# STM32F407 register map
File version: 1.4
CPU: CM4 r0p1, little endian, MPU, FPU, 4 interrupt priority bits
Registers are 32-bit, read-write, reset 0x0 unless marked. A register's access mark holds for its fields unless they carry their own. Offsets are from the block's base; [hi:lo] are bit positions; {n}, {i} and the like mark numbered series; 'fields as' and 'values as' point back to an identical list.

## OTG_FS_PWRCLK — USB on the go full speed
Base 0x50000E00
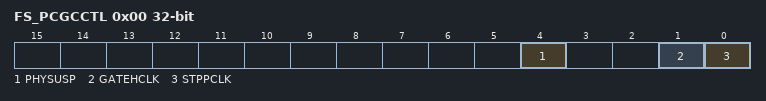
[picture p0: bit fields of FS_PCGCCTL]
0x00 FS_PCGCCTL — OTG_FS power and clock gating control register
  [4] PHYSUSP — PHY Suspended
  [1] GATEHCLK
  [0] STPPCLK — Stop PHY clock

## OTG_HS_PWRCLK — USB on the go high speed
Base 0x40040E00
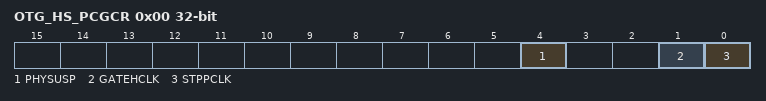
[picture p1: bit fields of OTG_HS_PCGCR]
0x00 OTG_HS_PCGCR — Power and clock gating control register
  [4] PHYSUSP — PHY suspended
  [1] GATEHCLK
  [0] STPPCLK — Stop PHY clock

## FLASH
Base 0x40023C00
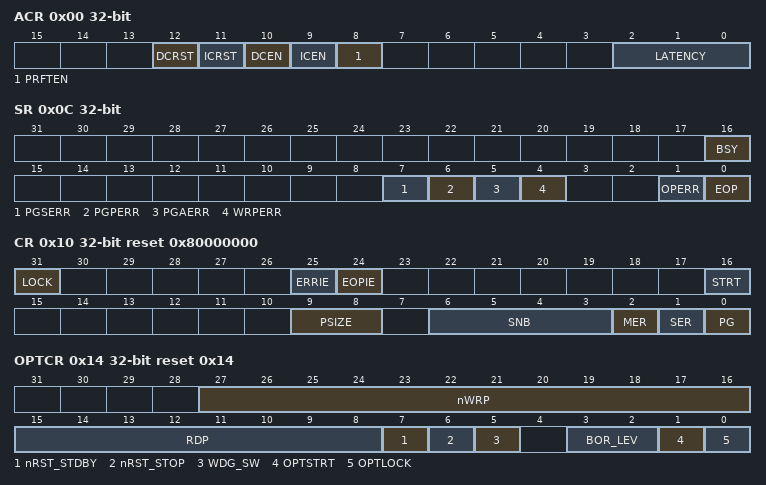
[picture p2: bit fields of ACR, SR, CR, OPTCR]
0x00 ACR access per field — Flash access control register
  [12] DCRST rw — Data cache reset
  [11] ICRST wo — Instruction cache reset
  [10] DCEN rw — Data cache enable
  [9] ICEN rw — Instruction cache enable
  [8] PRFTEN rw — Prefetch enable
  [2:0] LATENCY rw
0x04 KEYR wo — Flash key register
  [31:0] KEY — FPEC key
0x08 OPTKEYR wo — Flash option key register
  [31:0] OPTKEY — Option byte key
0x0C SR access per field — Status register
  [16] BSY ro — Busy
  [7] PGSERR rw — Programming sequence error
  [6] PGPERR rw — Programming parallelism error
  [5] PGAERR rw — Programming alignment error
  [4] WRPERR rw — Write protection error
  [1] OPERR rw — Operation error
  [0] EOP rw — End of operation
0x10 CR reset 0x80000000 — Control register
  [31] LOCK
  [25] ERRIE — Error interrupt enable
  [24] EOPIE — End of operation interrupt enable
  [16] STRT — Start
  [9:8] PSIZE — Program size
  [6:3] SNB — Sector number
  [2] MER — Mass Erase
  [1] SER — Sector Erase
  [0] PG — Programming
0x14 OPTCR reset 0x14 — Flash option control register
  [27:16] nWRP — Not write protect
  [15:8] RDP — Read protect
  [7] nRST_STDBY — nRST_STDBY User option bytes
  [6] nRST_STOP — nRST_STOP User option bytes
  [5] WDG_SW — WDG_SW User option bytes
  [3:2] BOR_LEV — BOR reset Level
  [1] OPTSTRT — Option start
  [0] OPTLOCK — Option lock

## EXTI — External interrupt/event controller
Base 0x40013C00
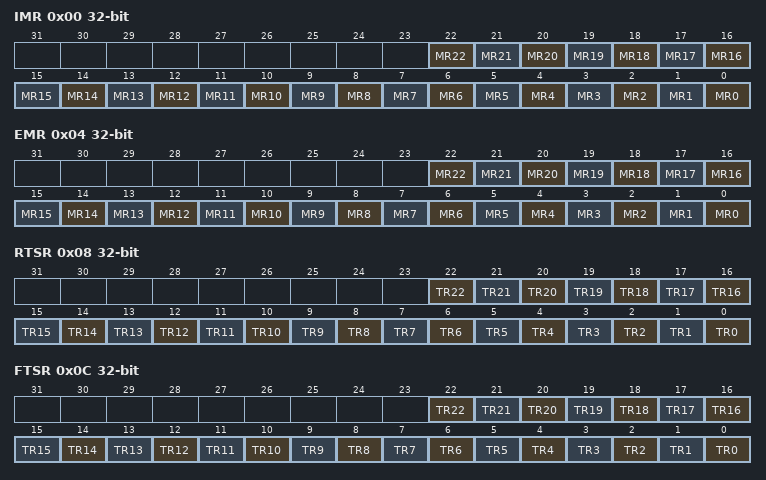
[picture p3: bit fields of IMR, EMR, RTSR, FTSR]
0x00 IMR — Interrupt mask register (EXTI_IMR)
  [n] MR{n} (n=0..22) — Interrupt Mask on line {n}
0x04 EMR — Event mask register (EXTI_EMR)
  [n] MR{n} (n=0..22) — Event Mask on line {n}
0x08 RTSR — Rising Trigger selection register (EXTI_RTSR)
  [n] TR{n} (n=0..22) — Rising trigger event configuration of line {n}
0x0C FTSR — Falling Trigger selection register (EXTI_FTSR)
  [n] TR{n} (n=0..22) — Falling trigger event configuration of line {n}
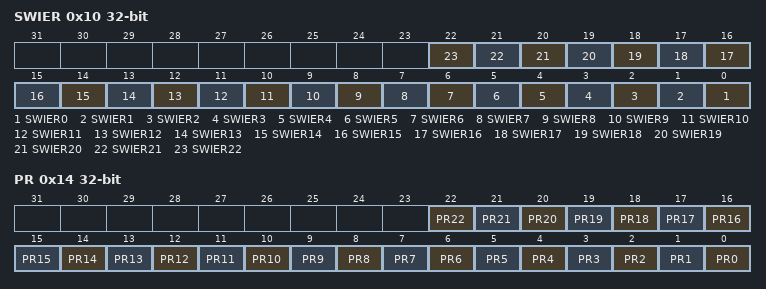
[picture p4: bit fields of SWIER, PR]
0x10 SWIER — Software interrupt event register (EXTI_SWIER)
  [n] SWIER{n} (n=0..22) — Software Interrupt on line {n}
0x14 PR — Pending register (EXTI_PR)
  [n] PR{n} (n=0..22) — Pending bit {n}

## NVIC — Nested Vectored Interrupt Controller
Base 0xE000E100
{0x0+4i} ISER{i} (i=0..2) — Interrupt Set-Enable Register
  [31:0] SETENA
{0x80+4i} ICER{i} (i=0..2) — Interrupt Clear-Enable Register
  [31:0] CLRENA
{0x100+4i} ISPR{i} (i=0..2) — Interrupt Set-Pending Register
  [31:0] SETPEND
{0x180+4i} ICPR{i} (i=0..2) — Interrupt Clear-Pending Register
  [31:0] CLRPEND
{0x200+4i} IABR{i} ro (i=0..2) — Interrupt Active Bit Register
  [31:0] ACTIVE
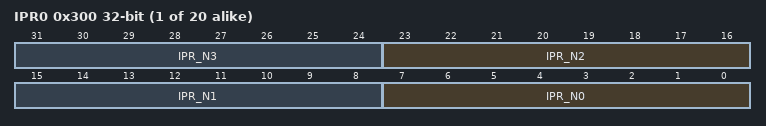
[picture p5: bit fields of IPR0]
{0x300+4i} IPR{i} (i=0..19) — Interrupt Priority Register
  [8n+7:8n] IPR_N{n} (n=0..3)

## SAI1 — Serial audio interface
Base 0x40015800
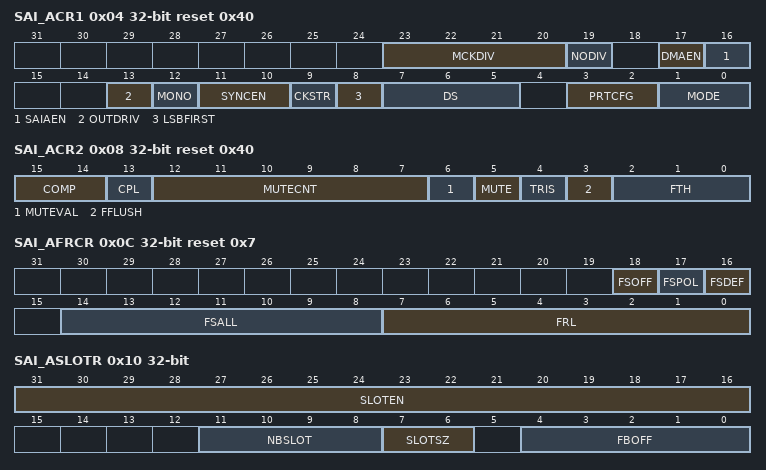
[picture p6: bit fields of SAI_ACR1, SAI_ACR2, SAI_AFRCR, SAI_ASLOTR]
0x04 SAI_ACR1 reset 0x40 — SAI AConfiguration register 1
  [23:20] MCKDIV — Master clock divider
  [19] NODIV — No divider
  [17] DMAEN — DMA enable
  [16] SAIAEN — Audio block enable
  [13] OUTDRIV — Output drive
  [12] MONO — Mono mode
  [11:10] SYNCEN — Synchronization enable
  [9] CKSTR — Clock strobing edge
  [8] LSBFIRST — Least significant bit first
  [7:5] DS — Data size
  [3:2] PRTCFG — Protocol configuration
  [1:0] MODE — Audio block mode
0x08 SAI_ACR2 reset 0x40 — SAI AConfiguration register 2
  [15:14] COMP — Companding mode
  [13] CPL — Complement bit
  [12:7] MUTECNT — Mute counter
  [6] MUTEVAL — Mute value
  [5] MUTE
  [4] TRIS — Tristate management on data line
  [3] FFLUSH — FIFO flush
  [2:0] FTH — FIFO threshold
0x0C SAI_AFRCR access per field reset 0x7 — SAI AFrame configuration register
  [18] FSOFF rw — Frame synchronization offset
  [17] FSPOL rw — Frame synchronization polarity
  [16] FSDEF ro — Frame synchronization definition
  [14:8] FSALL rw — Frame synchronization active level length
  [7:0] FRL rw — Frame length
0x10 SAI_ASLOTR — SAI ASlot register
  [31:16] SLOTEN — Slot enable
  [11:8] NBSLOT — Number of slots in an audio frame
  [7:6] SLOTSZ — Slot size
  [4:0] FBOFF — First bit offset
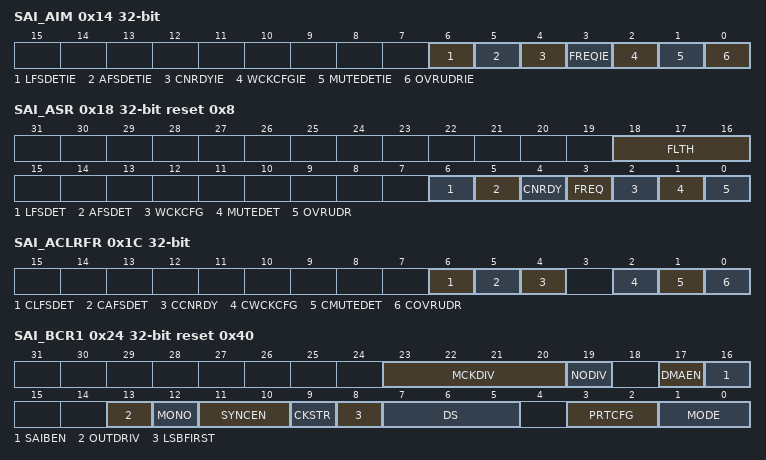
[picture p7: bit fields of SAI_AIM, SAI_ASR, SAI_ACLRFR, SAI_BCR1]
0x14 SAI_AIM — SAI AInterrupt mask register2
  [6] LFSDETIE — Late frame synchronization detection interrupt enable
  [5] AFSDETIE — Anticipated frame synchronization detection interrupt enable
  [4] CNRDYIE — Codec not ready interrupt enable
  [3] FREQIE — FIFO request interrupt enable
  [2] WCKCFGIE — Wrong clock configuration interrupt enable
  [1] MUTEDETIE — Mute detection interrupt enable
  [0] OVRUDRIE — Overrun/underrun interrupt enable
0x18 SAI_ASR ro reset 0x8 — SAI AStatus register
  [18:16] FLTH — FIFO level threshold
  [6] LFSDET — Late frame synchronization detection
  [5] AFSDET — Anticipated frame synchronization detection
  [4] CNRDY — Codec not ready
  [3] FREQ — FIFO request
  [2] WCKCFG — Wrong clock configuration flag
  [1] MUTEDET — Mute detection
  [0] OVRUDR — Overrun / underrun
0x1C SAI_ACLRFR — SAI AClear flag register
  [6] CLFSDET — Clear late frame synchronization detection flag
  [5] CAFSDET — Clear anticipated frame synchronization detection flag
  [4] CCNRDY — Clear codec not ready flag
  [2] CWCKCFG — Clear wrong clock configuration flag
  [1] CMUTEDET — Mute detection flag
  [0] COVRUDR — Clear overrun / underrun
0x20 SAI_ADR — SAI AData register
  [31:0] DATA
0x24 SAI_BCR1 reset 0x40 — SAI BConfiguration register 1
  [23:20] MCKDIV — Master clock divider
  [19] NODIV — No divider
  [17] DMAEN — DMA enable
  [16] SAIBEN — Audio block enable
  [13] OUTDRIV — Output drive
  [12] MONO — Mono mode
  [11:10] SYNCEN — Synchronization enable
  [9] CKSTR — Clock strobing edge
  [8] LSBFIRST — Least significant bit first
  [7:5] DS — Data size
  [3:2] PRTCFG — Protocol configuration
  [1:0] MODE — Audio block mode
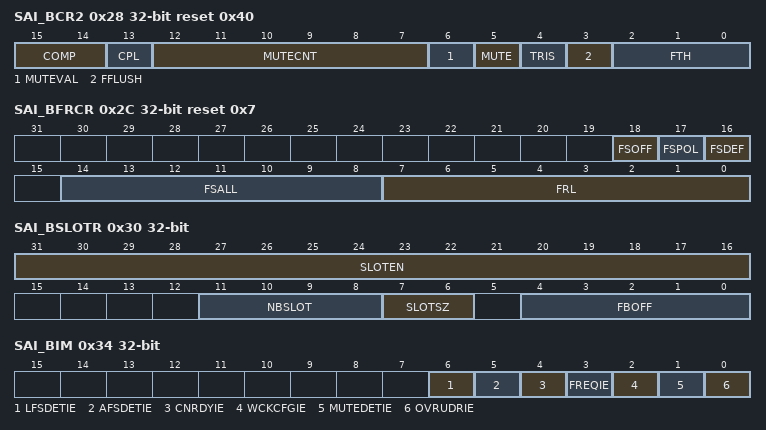
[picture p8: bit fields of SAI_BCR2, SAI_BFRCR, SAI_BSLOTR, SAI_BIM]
0x28 SAI_BCR2 reset 0x40 — SAI BConfiguration register 2
  fields as SAI_ACR2
0x2C SAI_BFRCR access per field reset 0x7 — SAI BFrame configuration register
  fields as SAI_AFRCR
0x30 SAI_BSLOTR — SAI BSlot register
  fields as SAI_ASLOTR
0x34 SAI_BIM — SAI BInterrupt mask register2
  fields as SAI_AIM
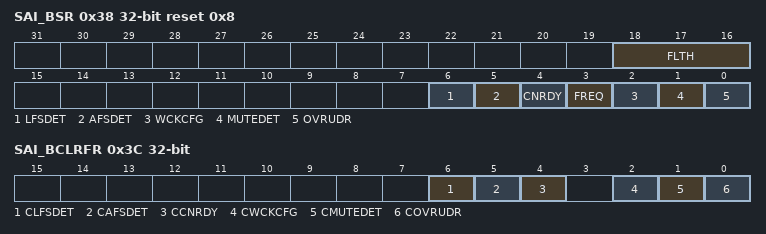
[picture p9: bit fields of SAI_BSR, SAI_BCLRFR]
0x38 SAI_BSR ro reset 0x8 — SAI BStatus register
  fields as SAI_ASR
0x3C SAI_BCLRFR — SAI BClear flag register
  fields as SAI_ACLRFR
0x40 SAI_BDR — SAI BData register
  [31:0] DATA
